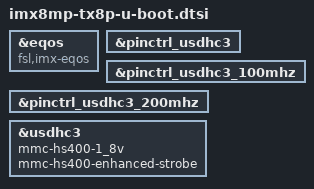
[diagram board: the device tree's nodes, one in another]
// SPDX-License-Identifier: (GPL-2.0 OR MIT)
/*
 * Copyright (C) 2021 Lothar Waßmann <LW@KARO-electronics.de>
 *
 */
#include "imx8m-tx8m-u-boot.dtsi"

&eqos {
	compatible = "fsl,imx-eqos";
	/delete-property/ assigned-clocks;
	/delete-property/ assigned-clock-parents;
	/delete-property/ assigned-clock-rates;
};

&pinctrl_usdhc3 {
	u-boot,dm-spl;
};

&pinctrl_usdhc3_100mhz {
	u-boot,dm-spl;
};

&pinctrl_usdhc3_200mhz {
	u-boot,dm-spl;
};

&usdhc3 {
	mmc-hs400-1_8v;
	mmc-hs400-enhanced-strobe;
	u-boot,dm-spl;
};
